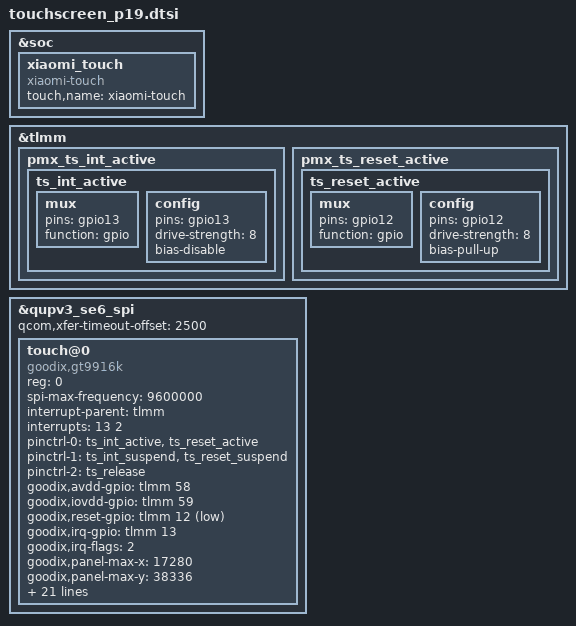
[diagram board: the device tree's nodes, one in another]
// SPDX-License-Identifier: BSD-3-Clause

&soc {
	xiaomi_touch {
		status = "ok";
		compatible = "xiaomi-touch";
		touch,name = "xiaomi-touch";
	};
};

&tlmm {
	pmx_ts_int_active {
		ts_int_active: ts_int_active {
			mux {
				pins = "gpio13";
				function = "gpio";
			};

			config {
				pins = "gpio13";
				drive-strength = <8>;
				bias-disable;
			};
		};
	};

	pmx_ts_reset_active {
		ts_reset_active: ts_reset_active {
			mux {
				pins = "gpio12";
				function = "gpio";
			};

			config {
				pins = "gpio12";
				drive-strength = <8>;
				bias-pull-up;
			};
		};
	};
};

/*
 * Goodix GT9916K or FocalTech FT3683G on SE6 SPI, one node like stock so
 * only one driver binds.
 */
&qupv3_se6_spi {
	#address-cells = <1>;
	#size-cells = <0>;
	qcom,xfer-timeout-offset = <2500>;
	status = "ok";

	touch@0 {
		compatible = "goodix,gt9916k", "goodix,brl-d", "fts_ts";
		reg = <0>;
		spi-max-frequency = <9600000>;
		interrupt-parent = <&tlmm>;
		interrupts = <13 2>;
		pinctrl-names = "pmx_ts_active", "pmx_ts_suspend", "pmx_ts_release";
		pinctrl-0 = <&ts_int_active &ts_reset_active>;
		pinctrl-1 = <&ts_int_suspend &ts_reset_suspend>;
		pinctrl-2 = <&ts_release>;
		goodix,avdd-gpio = <&tlmm 58 0>;
		goodix,iovdd-gpio = <&tlmm 59 0>;
		goodix,reset-gpio = <&tlmm 12 1>;
		goodix,irq-gpio = <&tlmm 13 2>;
		goodix,irq-flags = <2>;
		goodix,panel-max-x = <17280>;
		goodix,panel-max-y = <38336>;
		goodix,panel-max-w = <255>;
		goodix,firmware-name = "goodix_firmware.bin";
		goodix,config-name = "goodix_cfg_group.bin";
		goodix,3rd-firmware-name = "goodix_3rd_firmware.bin";
		goodix,3rd-config-name = "goodix_3rd_cfg_group.bin";
		focaltech,avdd-gpio = <&tlmm 58 0>;
		focaltech,iovdd-gpio = <&tlmm 59 0>;
		focaltech,reset-gpio = <&tlmm 12 1>;
		focaltech,irq-gpio = <&tlmm 13 2>;
		focaltech,irq-flags = <2>;
		focaltech,max-touch-number = <10>;
		focaltech,display-coords = <0 0 1079 2395>;
		panel = <&dsi_p19_38_0e_0a_video_dphy &dsi_p19_38_0e_0a_p11_video_dphy
			 &dsi_p19_38_0e_0a_p20_video_dphy &dsi_p19_38_0e_0a_new_p10_video_dphy
			 &dsi_p19_38_0e_0a_new_p11_video_dphy &dsi_p19_38_0e_0a_new_p20_video_dphy
			 &dsi_p19_38_0e_0a_mp_video_dphy>;
		status = "ok";
	};
};
